# f29h85x_memss_c_config_regs register map
Vendor: Texas Instruments
Peripheral module from a debugger description file (folder C29).
Registers are 32-bit, read-write, no defined reset value unless marked. A register's access mark holds for its fields unless they carry their own. Offsets are as the file gives them; lines under a group give offsets from that group; [hi:lo] are bit positions; {n}, {i} and the like mark numbered series; 'fields as' and 'values as' point back to an identical list; <NAME> marks a mode.

## MEMSS_C_CONFIG_REGS — MEMSS C CONFIG Registers
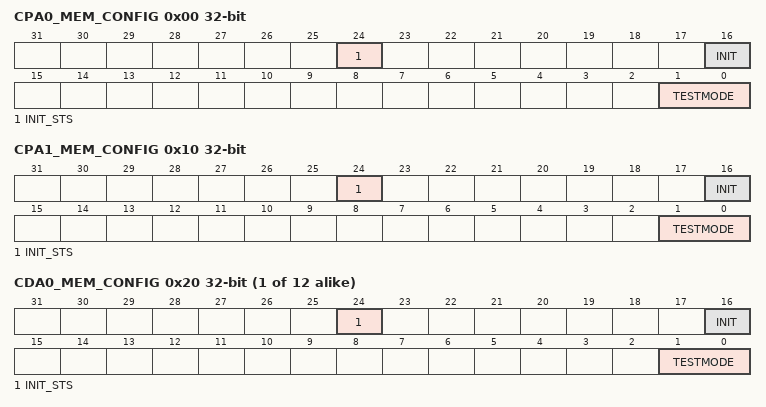
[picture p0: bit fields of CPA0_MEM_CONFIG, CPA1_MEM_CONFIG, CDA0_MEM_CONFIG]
0x00 CPA0_MEM_CONFIG access per field — CPA0 Memory Configuration Register
  [24] INIT_STS ro — CPA0 INIT status
  [16] INIT rw — Triggers memory Initilization
  [1:0] TESTMODE rw — LPA0 Test Mode
0x04 CPA0_MEM_CONFIG_LOCK — Temporary Lock for CPA0 Memory Configuration Register
  [0] CPA0_MEM_CONFIG — Temporary Lock
0x08 CPA0_MEM_CONFIG_COMMIT — Permament Lock for CPA0 Memory Configuration Register
  [0] CPA0_MEM_CONFIG_LOCK — Permanent Commit
0x10 CPA1_MEM_CONFIG access per field — CPA1 Memory Configuration Register
  [24] INIT_STS ro — CPA1 INIT status
  [16] INIT rw — Triggers memory Initilization
  [1:0] TESTMODE rw — LPA1 Test Mode
0x14 CPA1_MEM_CONFIG_LOCK — Temporary Lock for CPA1 Memory Configuration Register
  [0] CPA1_MEM_CONFIG — Temporary Lock
0x18 CPA1_MEM_CONFIG_COMMIT — Permament Lock for CPA1 Memory Configuration Register
  [0] CPA1_MEM_CONFIG_LOCK — Permanent Commit
{0x20+0x10*i} CDA{i}_MEM_CONFIG access per field (i=0..11) — CDA{i} Memory Configuration Register
  [24] INIT_STS ro — CDA{i} INIT status
  [16] INIT rw — Triggers memory Initilization
  [1:0] TESTMODE rw — LDA{i} Test Mode
{0x24+0x10*i} CDA{i}_MEM_CONFIG_LOCK (i=0..11) — Temporary Lock for CDA{i} Memory Configuration Register
  [0] CDA{i}_MEM_CONFIG — Temporary Lock
{0x28+0x10*i} CDA{i}_MEM_CONFIG_COMMIT (i=0..11) — Permament Lock for CDA{i} Memory Configuration Register
  [0] CDA{i}_MEM_CONFIG_LOCK — Permanent Commit
